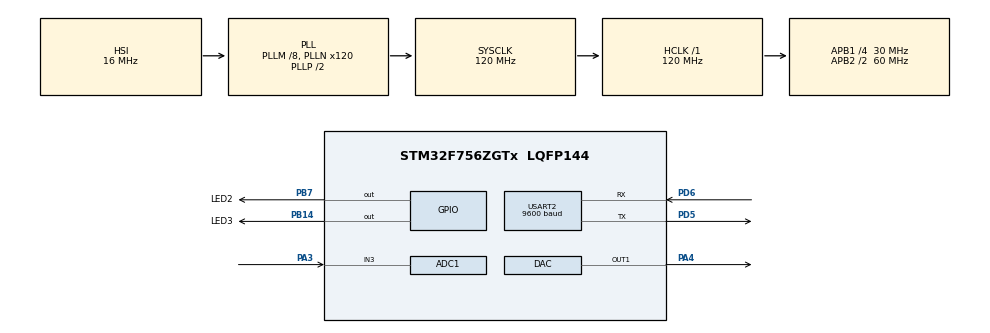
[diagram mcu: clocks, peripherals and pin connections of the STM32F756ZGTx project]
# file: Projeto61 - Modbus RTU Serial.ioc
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ADC1.Channel-0\#ChannelRegularConversion=ADC_CHANNEL_3
ADC1.ContinuousConvMode=ENABLE
ADC1.DMAContinuousRequests=ENABLE
ADC1.NbrOfConversionFlag=1
ADC1.Rank-0\#ChannelRegularConversion=1
ADC1.SamplingTime-0\#ChannelRegularConversion=ADC_SAMPLETIME_3CYCLES
ADC1.ScanConvMode=ADC_SCAN_ENABLE
ADC1.master=1
CORTEX_M7.ART_ACCELERATOR_ENABLE=0
Dma.ADC1.1.Direction=DMA_PERIPH_TO_MEMORY
Dma.ADC1.1.FIFOMode=DMA_FIFOMODE_DISABLE
Dma.ADC1.1.Instance=DMA2_Stream0
Dma.ADC1.1.MemDataAlignment=DMA_MDATAALIGN_HALFWORD
Dma.ADC1.1.MemInc=DMA_MINC_ENABLE
Dma.ADC1.1.Mode=DMA_CIRCULAR
Dma.ADC1.1.PeriphDataAlignment=DMA_PDATAALIGN_HALFWORD
Dma.ADC1.1.PeriphInc=DMA_PINC_DISABLE
Dma.ADC1.1.Priority=DMA_PRIORITY_LOW
Dma.Request0=USART2_RX
Dma.Request1=ADC1
Dma.USART2_RX.0.Direction=DMA_PERIPH_TO_MEMORY
Dma.USART2_RX.0.FIFOMode=DMA_FIFOMODE_DISABLE
Dma.USART2_RX.0.Instance=DMA1_Stream5
Dma.USART2_RX.0.MemDataAlignment=DMA_MDATAALIGN_BYTE
Dma.USART2_RX.0.MemInc=DMA_MINC_ENABLE
Dma.USART2_RX.0.Mode=DMA_CIRCULAR
Dma.USART2_RX.0.PeriphDataAlignment=DMA_PDATAALIGN_BYTE
Dma.USART2_RX.0.PeriphInc=DMA_PINC_DISABLE
Dma.USART2_RX.0.Priority=DMA_PRIORITY_VERY_HIGH
Mcu.Family=STM32F7
Mcu.Name=STM32F756ZGTx
Mcu.Package=LQFP144
NVIC.DMA1_Stream5_IRQn=true\:0\:0\:false\:false\:true\:false\:true\:true
NVIC.DMA2_Stream0_IRQn=true\:0\:0\:false\:false\:true\:false\:true\:true
NVIC.PriorityGroup=NVIC_PRIORITYGROUP_4
NVIC.USART2_IRQn=true\:0\:0\:false\:false\:true\:true\:true\:true
PA3.Signal=ADCx_IN3
PA4.Signal=COMP_DAC1_group
PB14.GPIO_Label=LED3
PB14.Signal=GPIO_Output
PB7.GPIO_Label=LED2
PB7.Signal=GPIO_Output
PD5.Mode=Asynchronous
PD5.Signal=USART2_TX
PD6.Mode=Asynchronous
PD6.Signal=USART2_RX
PH0/OSC_IN.Mode=HSE-External-Clock-Source
PH0/OSC_IN.Signal=RCC_OSC_IN
PH1/OSC_OUT.Mode=HSE-External-Clock-Source
PH1/OSC_OUT.Signal=RCC_OSC_OUT
ProjectManager.HeapSize=0x200
ProjectManager.StackSize=0x400
ProjectManager.TargetToolchain=STM32CubeIDE
RCC.48MHZClocksFreq_Value=24000000
RCC.AHBFreq_Value=120000000
RCC.APB1CLKDivider=RCC_HCLK_DIV4
RCC.APB1Freq_Value=30000000
RCC.APB1TimFreq_Value=60000000
RCC.APB2CLKDivider=RCC_HCLK_DIV2
RCC.APB2Freq_Value=60000000
RCC.APB2TimFreq_Value=120000000
RCC.CortexFreq_Value=120000000
RCC.HCLKFreq_Value=120000000
RCC.HSE_VALUE=8000000
RCC.HSI_VALUE=16000000
RCC.LSE_VALUE=32768
RCC.PLLM=8
RCC.PLLMUL=RCC_PLL_MUL9
RCC.PLLN=120
RCC.PLLQ=3
RCC.PRESCALERUSB=RCC_USBCLKSOURCE_PLL_DIV1_5
RCC.SYSCLKFreq_VALUE=120000000
RCC.SYSCLKSource=RCC_SYSCLKSOURCE_PLLCLK
RCC.SYSCLKSourceVirtual=RCC_SYSCLKSOURCE_PLLCLK
RCC.USBFreq_Value=80000000
RCC.VCOOutputFreq_Value=240000000
SH.ADCx_IN3.0=ADC1_IN3,IN3
SH.COMP_DAC1_group.0=DAC_OUT1,DAC_OUT1
USART2.BaudRate=9600
USART2.VirtualMode-Asynchronous=VM_ASYNC
board=NUCLEO-F756ZG

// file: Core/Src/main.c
/* USER CODE BEGIN Header */
/**
  ******************************************************************************
  * @file           : main.c
  * @brief          : Main program body
  ******************************************************************************
  * @attention
  *
  * Copyright (c) 2023 STMicroelectronics.
  * All rights reserved.
  *
  * This software is licensed under terms that can be found in the LICENSE file
  * in the root directory of this software component.
  * If no LICENSE file comes with this software, it is provided AS-IS.
  *
  ******************************************************************************
  */
/* USER CODE END Header */
#include "main.h"

/* USER CODE BEGIN Includes */

#include "stdio.h"
#include "stdlib.h"
#include "string.h"
#include "gpio.h"

/* USER CODE END Includes */

 ADC_HandleTypeDef hadc1;
DMA_HandleTypeDef hdma_adc1;

DAC_HandleTypeDef hdac;

UART_HandleTypeDef huart2;
DMA_HandleTypeDef hdma_usart2_rx;

/* USER CODE BEGIN PV */

uint8_t buffe_rx[8];

uint16_t adc_dados; //Variável Para Leitura Adc;
uint8_t adc_dados_byte_maior; //Posicionamento da Variável no Byte Maior;
uint8_t adc_dados_byte_menor; //Posicionamento da Variável no Byte Menor;

/* USER CODE END PV */

void SystemClock_Config(void);
static void MX_GPIO_Init(void);
static void MX_DMA_Init(void);
static void MX_ADC1_Init(void);
static void MX_DAC_Init(void);
static void MX_USART2_UART_Init(void);

int main(void)
{

  /* MCU Configuration--------------------------------------------------------*/

  /* Reset of all peripherals, Initializes the Flash interface and the Systick. */
  HAL_Init();

  /* Configure the system clock */
  SystemClock_Config();

  /* Initialize all configured peripherals */
  MX_GPIO_Init();
  MX_DMA_Init();
  MX_ADC1_Init();
  MX_DAC_Init();
  MX_USART2_UART_Init();
  /* USER CODE BEGIN 2 */

  HAL_UART_Receive_DMA(&huart2, buffe_rx, sizeof(buffe_rx)); //Recebe Dados Serial via DMA;
//  HAL_ADC_Start_DMA(&hadc1, &adc_dados, 1); //Recebe Dados Do ADC via DMA;
//  HAL_DAC_Start(&hdac, DAC_CHANNEL_1); //Inicializa DAC;

  //Condição Inicial do DAC (Saída Analógica)
//  HAL_DAC_SetValue(&hdac, DAC_CHANNEL_1, DAC_ALIGN_12B_R, 0);

  //Condições Inicial dos Leds (Coils);
  GPIO_init_leds();

  /* USER CODE END 2 */

  /* Infinite loop */
  while (1)
  {

    /* USER CODE BEGIN 3 */

	  //Atualiza Dados de ADC nos Bytes Maiores e Menores:
	  adc_dados_byte_maior=adc_dados>>8;
	  adc_dados_byte_menor=adc_dados;
  }
  /* USER CODE END 3 */
}

void SystemClock_Config(void)
{
  RCC_OscInitTypeDef RCC_OscInitStruct = {0};
  RCC_ClkInitTypeDef RCC_ClkInitStruct = {0};

  /** Configure the main internal regulator output voltage
  */
  __HAL_RCC_PWR_CLK_ENABLE();
  __HAL_PWR_VOLTAGESCALING_CONFIG(PWR_REGULATOR_VOLTAGE_SCALE3);

  /** Initializes the RCC Oscillators according to the specified parameters
  * in the RCC_OscInitTypeDef structure.
  */
  RCC_OscInitStruct.OscillatorType = RCC_OSCILLATORTYPE_HSI;
  RCC_OscInitStruct.HSIState = RCC_HSI_ON;
  RCC_OscInitStruct.HSICalibrationValue = RCC_HSICALIBRATION_DEFAULT;
  RCC_OscInitStruct.PLL.PLLState = RCC_PLL_ON;
  RCC_OscInitStruct.PLL.PLLSource = RCC_PLLSOURCE_HSI;
  RCC_OscInitStruct.PLL.PLLM = 8;
  RCC_OscInitStruct.PLL.PLLN = 120;
  RCC_OscInitStruct.PLL.PLLP = RCC_PLLP_DIV2;
  RCC_OscInitStruct.PLL.PLLQ = 3;
  if (HAL_RCC_OscConfig(&RCC_OscInitStruct) != HAL_OK)
  {
    Error_Handler();
  }

  /** Initializes the CPU, AHB and APB buses clocks
  */
  RCC_ClkInitStruct.ClockType = RCC_CLOCKTYPE_HCLK|RCC_CLOCKTYPE_SYSCLK
                              |RCC_CLOCKTYPE_PCLK1|RCC_CLOCKTYPE_PCLK2;
  RCC_ClkInitStruct.SYSCLKSource = RCC_SYSCLKSOURCE_PLLCLK;
  RCC_ClkInitStruct.AHBCLKDivider = RCC_SYSCLK_DIV1;
  RCC_ClkInitStruct.APB1CLKDivider = RCC_HCLK_DIV4;
  RCC_ClkInitStruct.APB2CLKDivider = RCC_HCLK_DIV2;

  if (HAL_RCC_ClockConfig(&RCC_ClkInitStruct, FLASH_LATENCY_3) != HAL_OK)
  {
    Error_Handler();
  }
}

static void MX_ADC1_Init(void)
{

  ADC_ChannelConfTypeDef sConfig = {0};

  /** Configure the global features of the ADC (Clock, Resolution, Data Alignment and number of conversion)
  */
  hadc1.Instance = ADC1;
  hadc1.Init.ClockPrescaler = ADC_CLOCK_SYNC_PCLK_DIV2;
  hadc1.Init.Resolution = ADC_RESOLUTION_12B;
  hadc1.Init.ScanConvMode = ADC_SCAN_ENABLE;
  hadc1.Init.ContinuousConvMode = ENABLE;
  hadc1.Init.DiscontinuousConvMode = DISABLE;
  hadc1.Init.ExternalTrigConvEdge = ADC_EXTERNALTRIGCONVEDGE_NONE;
  hadc1.Init.ExternalTrigConv = ADC_SOFTWARE_START;
  hadc1.Init.DataAlign = ADC_DATAALIGN_RIGHT;
  hadc1.Init.NbrOfConversion = 1;
  hadc1.Init.DMAContinuousRequests = ENABLE;
  hadc1.Init.EOCSelection = ADC_EOC_SINGLE_CONV;
  if (HAL_ADC_Init(&hadc1) != HAL_OK)
  {
    Error_Handler();
  }

  /** Configure for the selected ADC regular channel its corresponding rank in the sequencer and its sample time.
  */
  sConfig.Channel = ADC_CHANNEL_3;
  sConfig.Rank = ADC_REGULAR_RANK_1;
  sConfig.SamplingTime = ADC_SAMPLETIME_3CYCLES;
  if (HAL_ADC_ConfigChannel(&hadc1, &sConfig) != HAL_OK)
  {
    Error_Handler();
  }

}

static void MX_DAC_Init(void)
{

  DAC_ChannelConfTypeDef sConfig = {0};

  /** DAC Initialization
  */
  hdac.Instance = DAC;
  if (HAL_DAC_Init(&hdac) != HAL_OK)
  {
    Error_Handler();
  }

  /** DAC channel OUT1 config
  */
  sConfig.DAC_Trigger = DAC_TRIGGER_NONE;
  sConfig.DAC_OutputBuffer = DAC_OUTPUTBUFFER_ENABLE;
  if (HAL_DAC_ConfigChannel(&hdac, &sConfig, DAC_CHANNEL_1) != HAL_OK)
  {
    Error_Handler();
  }

}

static void MX_USART2_UART_Init(void)
{

  huart2.Instance = USART2;
  huart2.Init.BaudRate = 9600;
  huart2.Init.WordLength = UART_WORDLENGTH_8B;
  huart2.Init.StopBits = UART_STOPBITS_1;
  huart2.Init.Parity = UART_PARITY_NONE;
  huart2.Init.Mode = UART_MODE_TX_RX;
  huart2.Init.HwFlowCtl = UART_HWCONTROL_NONE;
  huart2.Init.OverSampling = UART_OVERSAMPLING_16;
  huart2.Init.OneBitSampling = UART_ONE_BIT_SAMPLE_DISABLE;
  huart2.AdvancedInit.AdvFeatureInit = UART_ADVFEATURE_NO_INIT;
  if (HAL_UART_Init(&huart2) != HAL_OK)
  {
    Error_Handler();
  }

}

static void MX_DMA_Init(void)
{

  /* DMA controller clock enable */
  __HAL_RCC_DMA1_CLK_ENABLE();
  __HAL_RCC_DMA2_CLK_ENABLE();

  /* DMA interrupt init */
  /* DMA1_Stream5_IRQn interrupt configuration */
  HAL_NVIC_SetPriority(DMA1_Stream5_IRQn, 0, 0);
  HAL_NVIC_EnableIRQ(DMA1_Stream5_IRQn);
  /* DMA2_Stream0_IRQn interrupt configuration */
  HAL_NVIC_SetPriority(DMA2_Stream0_IRQn, 0, 0);
  HAL_NVIC_EnableIRQ(DMA2_Stream0_IRQn);

}

static void MX_GPIO_Init(void)
{
  GPIO_InitTypeDef GPIO_InitStruct = {0};

  /* GPIO Ports Clock Enable */
  __HAL_RCC_GPIOH_CLK_ENABLE();
  __HAL_RCC_GPIOA_CLK_ENABLE();
  __HAL_RCC_GPIOB_CLK_ENABLE();
  __HAL_RCC_GPIOD_CLK_ENABLE();

  /*Configure GPIO pin Output Level */
  HAL_GPIO_WritePin(GPIOB, LED3_Pin|LED2_Pin, GPIO_PIN_RESET);

  /*Configure GPIO pins : LED3_Pin LED2_Pin */
  GPIO_InitStruct.Pin = LED3_Pin|LED2_Pin;
  GPIO_InitStruct.Mode = GPIO_MODE_OUTPUT_PP;
  GPIO_InitStruct.Pull = GPIO_NOPULL;
  GPIO_InitStruct.Speed = GPIO_SPEED_FREQ_LOW;
  HAL_GPIO_Init(GPIOB, &GPIO_InitStruct);

}

void Error_Handler(void)
{
  __disable_irq();
  while (1)
  {
  }
}
